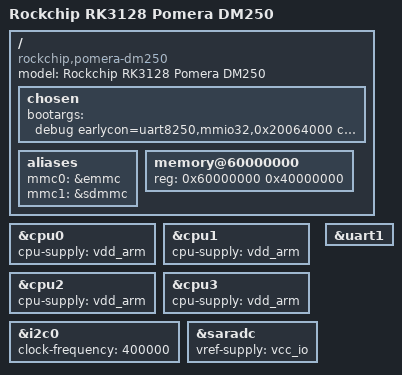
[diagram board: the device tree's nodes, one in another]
// SPDX-License-Identifier: (GPL-2.0+ OR MIT)
/dts-v1/;

#include "rk3128.dtsi"
#include "pomera-dm250-led.dtsi"
#include "pomera-dm250-kbd.dtsi"
#include "pomera-dm250-lcd.dtsi"
#include "pomera-dm250-power.dtsi"
#include "pomera-dm250-mmc.dtsi"
#include "pomera-dm250-usb.dtsi"
#include "pomera-dm250-wifi.dtsi"

#include <dt-bindings/gpio/gpio.h>
#include <dt-bindings/pinctrl/rockchip.h>
#include <dt-bindings/pwm/pwm.h>
#include <dt-bindings/input/input.h>

/ {
	model = "Rockchip RK3128 Pomera DM250";
	compatible = "rockchip,pomera-dm250", "rockchip,rk3128";

	chosen {
		bootargs = "debug earlycon=uart8250,mmio32,0x20064000 console=ttyS1,115200n8 root=/dev/mmcblk1p2 rw rootwait";
	};
	
	aliases {
		mmc0 = &emmc;
		mmc1 = &sdmmc;
	};
        
	memory@60000000 {
		device_type = "memory";
		reg = <0x60000000 0x40000000>;
	};
};

&cpu0 {
	cpu-supply = <&vdd_arm>;
};

&cpu1 {
	cpu-supply = <&vdd_arm>;
};

&cpu2 {
	cpu-supply = <&vdd_arm>;
};

&cpu3 {
	cpu-supply = <&vdd_arm>;
};

&i2c0 {
	status = "okay";
	clock-frequency = <400000>;
};

&saradc {
	status = "okay";
	vref-supply = <&vcc_io>;
};

/* for debug uart */
&uart1 {
        status = "okay";
};
